AUTOSAR XML (schema 00047)
package /ASW_NVM/NVM/ImplementationDataTypes
  impl type Impl_NVM_DstPtrType_1024: category=ARRAY
    element ArrayElement: array-size=1024, array-size-semantics=FIXED-SIZE, implementation-data-type=uint8
package /ASW_NVM/ASW_NVM
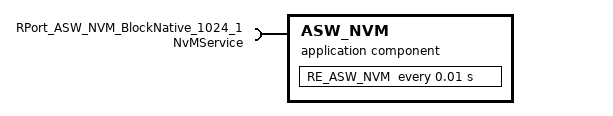
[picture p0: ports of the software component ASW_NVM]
  application sw component type ASW_NVM
    require port RPort_ASW_NVM_BlockNative_1024_1: required-interface=NvMService
    behavior IB_ASW_NVM: data-type-mapping=AppMode_Mapping
      timing event TE_ASW_NVM_10ms: start-on-event=RE_ASW_NVM, period=0.01
      per instance memory ASW_NVM_BlockNative_1024_1: implementation-data-type=Impl_NVM_DstPtrType_1024, type=ASW_NVM_BlockNative_1024_Type, type-definition=Impl_NVM_DstPtrType_1024
      per instance memory ASW_NVM_BlockNative_1024_2: implementation-data-type=Impl_NVM_DstPtrType_1024, type=ASW_NVM_BlockRedundant_1024_Type, type-definition=Impl_NVM_DstPtrType_1024
      runnable RE_ASW_NVM: symbol=RE_ASW_NVM_func
        9 x sync call:
          SynchronousServerCallPoint_0: operation=RPort_ASW_NVM_BlockNative_1024_1.EraseBlock
          SynchronousServerCallPoint_1: operation=RPort_ASW_NVM_BlockNative_1024_1.GetDataIndex
          SynchronousServerCallPoint_2: operation=RPort_ASW_NVM_BlockNative_1024_1.GetErrorStatus
          SynchronousServerCallPoint_3: operation=RPort_ASW_NVM_BlockNative_1024_1.InvalidateNvBlock
          SynchronousServerCallPoint_4: operation=RPort_ASW_NVM_BlockNative_1024_1.ReadBlock
          SynchronousServerCallPoint_5: operation=RPort_ASW_NVM_BlockNative_1024_1.RestoreBlockDefaults
          SynchronousServerCallPoint_6: operation=RPort_ASW_NVM_BlockNative_1024_1.SetDataIndex
          SynchronousServerCallPoint_7: operation=RPort_ASW_NVM_BlockNative_1024_1.SetRamBlockStatus
          SynchronousServerCallPoint_8: operation=RPort_ASW_NVM_BlockNative_1024_1.WriteBlock
      swc service dependency SwcServiceDependency: assigned-ports=role-based-port-assignment={port-prototype=RPort_ASW_NVM_BlockNative_1024_1, role=NvMService}
        assigned-datas:
          role=ramBlock, used-pim=ASW_NVM_BlockNative_1024_1
          role=ramBlock, used-pim=ASW_NVM_BlockNative_1024_2
        service-needs:
          nv block needs NvBlockNeeds_NvM: category=READ, calc-ram-block-crc=false, check-static-block-id=false, n-rom-blocks=0, readonly=false, restore-at-start=true, store-at-shutdown=true, store-cyclic=false, store-immediate=true, write-only-once=false
